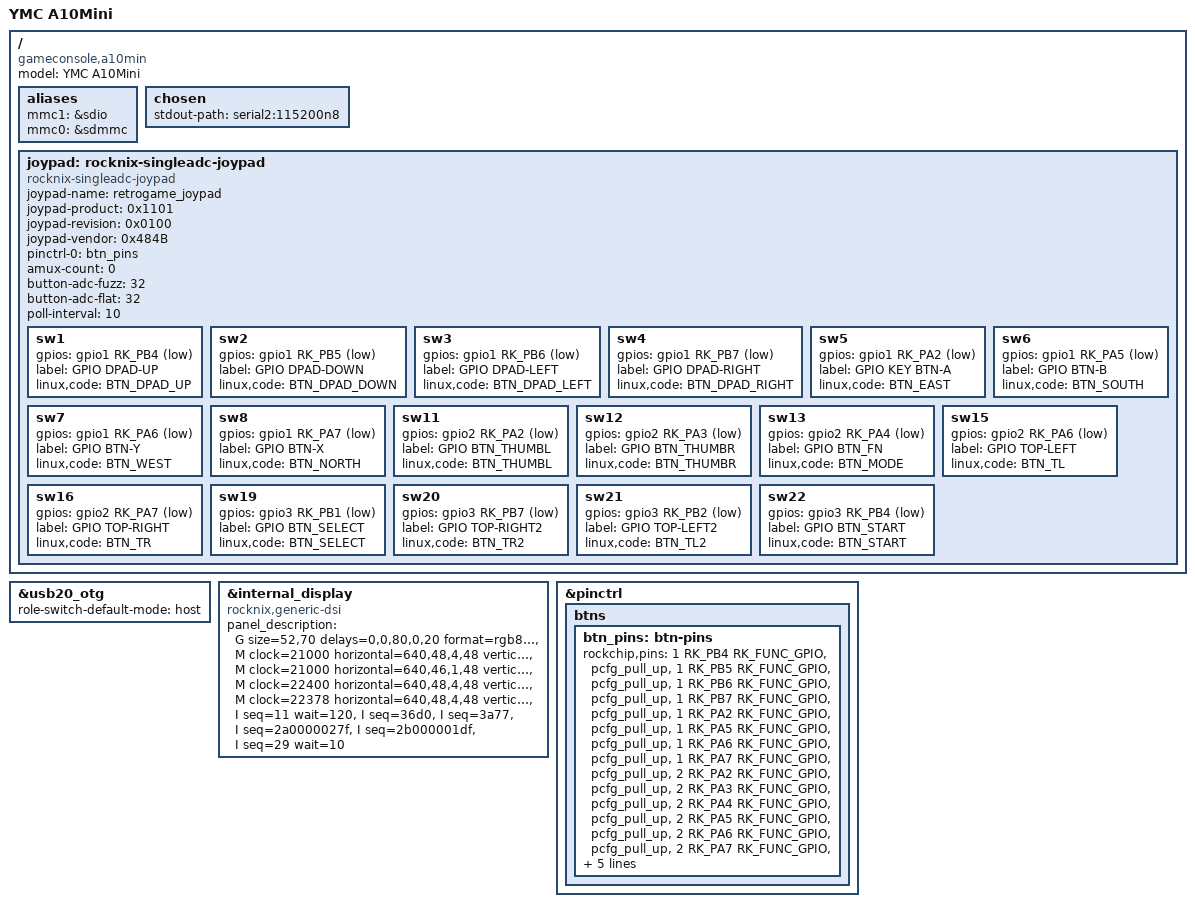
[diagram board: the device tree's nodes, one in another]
// SPDX-License-Identifier: (GPL-2.0+ OR MIT)
/*
* # Copyright (C) 2022-24 JELOS (https://github.com/JustEnoughLinuxOS)
*/

/dts-v1/;
#include "rk3326-gameconsole-r3xs.dtsi"

/ {
	model = "YMC A10Mini";
	compatible = "gameconsole,a10min", "rockchip,rk3326";
	
	aliases {
		mmc1 = &sdio;
		mmc0 = &sdmmc;
	};
	
	chosen {
		stdout-path = "serial2:115200n8";
	};
	
	joypad: rocknix-singleadc-joypad {
		compatible = "rocknix-singleadc-joypad";
		
		joypad-name = "retrogame_joypad";
		joypad-product = <0x1101>;
		joypad-revision = <0x0100>;
		joypad-vendor = <0x484B>;
		
		status = "okay";
		
		/* gpio pincontrol setup */
		pinctrl-names = "default";
		pinctrl-0 = <&btn_pins>;
		
		/* adc mux channel count */
		amux-count = <0>;
		
		/*
		specifies fuzz value that is used to filter noise from
		the event stream.
		*/
		button-adc-fuzz = <32>;
		button-adc-flat = <32>;
		
		
		/* poll device interval (ms), adc read interval */
		poll-interval = <10>;
		
		/* gpio button auto repeat set value : default disable */
		/*
		autorepeat;
		*/
		
		/*
		joypad driver is poll-device driver.
		poll-device is does not support wakeup-source.
		*/
		sw1 {
			gpios = <&gpio1 RK_PB4 GPIO_ACTIVE_LOW>;
			label = "GPIO DPAD-UP";
			linux,code = <BTN_DPAD_UP>;// 0x220
		};
		sw2 {
			gpios = <&gpio1 RK_PB5 GPIO_ACTIVE_LOW>;
			label = "GPIO DPAD-DOWN";
			linux,code = <BTN_DPAD_DOWN>;// 0x221
		};
		sw3 {
			gpios = <&gpio1 RK_PB6 GPIO_ACTIVE_LOW>;
			label = "GPIO DPAD-LEFT";
			linux,code = <BTN_DPAD_LEFT>;// 0x222
		};
		sw4 {
			gpios = <&gpio1 RK_PB7 GPIO_ACTIVE_LOW>;
			label = "GPIO DPAD-RIGHT";
			linux,code = <BTN_DPAD_RIGHT>;// 0x223
		};
		sw5 {
			gpios = <&gpio1 RK_PA2 GPIO_ACTIVE_LOW>;
			label = "GPIO KEY BTN-A";
			linux,code = <BTN_EAST>;// 0x131
		};
		sw6 {
			gpios = <&gpio1 RK_PA5 GPIO_ACTIVE_LOW>;
			label = "GPIO BTN-B";
			linux,code = <BTN_SOUTH>;// 0x130
		};
		sw7 {
			gpios = <&gpio1 RK_PA6 GPIO_ACTIVE_LOW>;
			label = "GPIO BTN-Y";
			linux,code = <BTN_WEST>;// 0x134
		};
		sw8 {
			gpios = <&gpio1 RK_PA7 GPIO_ACTIVE_LOW>;
			label = "GPIO BTN-X";
			linux,code = <BTN_NORTH>;// 0x133
		};
		sw11 {
			gpios = <&gpio2 RK_PA2 GPIO_ACTIVE_LOW>;
			label = "GPIO BTN_THUMBL";
			linux,code = <BTN_THUMBL>;// 0x2c2
		};
		sw12 {
			gpios = <&gpio2 RK_PA3 GPIO_ACTIVE_LOW>;
			label = "GPIO BTN_THUMBR";
			linux,code = <BTN_THUMBR>;// 0x2c3
		};
		sw13 {
			gpios = <&gpio2 RK_PA4 GPIO_ACTIVE_LOW>;
			label = "GPIO BTN_FN";
			linux,code = <BTN_MODE>;// 0x2c4
		};
		sw15 {
			gpios = <&gpio2 RK_PA6 GPIO_ACTIVE_LOW>;
			label = "GPIO TOP-LEFT";
			linux,code = <BTN_TL>;// 0x02
		};
		sw16 {
			gpios = <&gpio2 RK_PA7 GPIO_ACTIVE_LOW>;
			label = "GPIO TOP-RIGHT";
			linux,code = <BTN_TR>;// 0x05
		};
		sw19 {
			gpios = <&gpio3 RK_PB1 GPIO_ACTIVE_LOW>;
			label = "GPIO BTN_SELECT";
			linux,code = <BTN_SELECT>;
		};
		sw20 {
			gpios = <&gpio3 RK_PB7 GPIO_ACTIVE_LOW>;
			label = "GPIO TOP-RIGHT2";
			linux,code = <BTN_TR2>;
		};
		sw21 {
			gpios = <&gpio3 RK_PB2 GPIO_ACTIVE_LOW>;
			label = "GPIO TOP-LEFT2";
			linux,code = <BTN_TL2>;
		};
		sw22 {
			gpios = <&gpio3 RK_PB4 GPIO_ACTIVE_LOW>;
			label = "GPIO BTN_START";
			linux,code = <BTN_START>;
		};
	};
};

&usb20_otg {
	status = "okay";
	/delete-property/ usb-role-switch;
	role-switch-default-mode = "host";
};

&internal_display {
	compatible = "rocknix,generic-dsi";
	panel_description =
	"G size=52,70 delays=0,0,80,0,20 format=rgb888 lanes=2 flags=0xe03",
	
	"M clock=21000 horizontal=640,48,4,48 vertical=480,10,4,10 default=1",
	"M clock=21000 horizontal=640,46,1,48 vertical=480,3,2,10",
	"M clock=22400 horizontal=640,48,4,48 vertical=480,10,4,10",
	"M clock=22378 horizontal=640,48,4,48 vertical=480,10,4,10",
	
	"I seq=11 wait=120",
	"I seq=36d0",
	"I seq=3a77",
	"I seq=2a0000027f",
	"I seq=2b000001df",
	"I seq=29 wait=10";
};

&pinctrl {
	btns {
		btn_pins: btn-pins {
			rockchip,pins = <1 RK_PB4 RK_FUNC_GPIO &pcfg_pull_up>,
			<1 RK_PB5 RK_FUNC_GPIO &pcfg_pull_up>,
			<1 RK_PB6 RK_FUNC_GPIO &pcfg_pull_up>,
			<1 RK_PB7 RK_FUNC_GPIO &pcfg_pull_up>,
			<1 RK_PA2 RK_FUNC_GPIO &pcfg_pull_up>,
			<1 RK_PA5 RK_FUNC_GPIO &pcfg_pull_up>,
			<1 RK_PA6 RK_FUNC_GPIO &pcfg_pull_up>,
			<1 RK_PA7 RK_FUNC_GPIO &pcfg_pull_up>,
			<2 RK_PA2 RK_FUNC_GPIO &pcfg_pull_up>,
			<2 RK_PA3 RK_FUNC_GPIO &pcfg_pull_up>,
			<2 RK_PA4 RK_FUNC_GPIO &pcfg_pull_up>,
			<2 RK_PA5 RK_FUNC_GPIO &pcfg_pull_up>,
			<2 RK_PA6 RK_FUNC_GPIO &pcfg_pull_up>,
			<2 RK_PA7 RK_FUNC_GPIO &pcfg_pull_up>,
			<3 RK_PB1 RK_FUNC_GPIO &pcfg_pull_up>,
			<3 RK_PB2 RK_FUNC_GPIO &pcfg_pull_up>,
			<3 RK_PB4 RK_FUNC_GPIO &pcfg_pull_up>,
			<3 RK_PB7 RK_FUNC_GPIO &pcfg_pull_up>;
			
		};
		
	};
};
